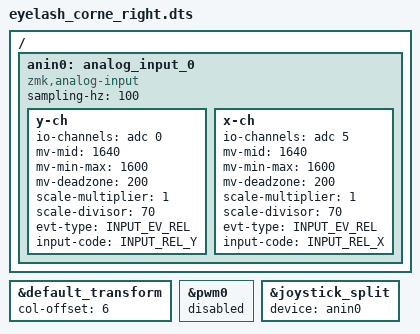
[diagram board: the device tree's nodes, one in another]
/*
*
* Copyright (c) 2024 The ZMK Contributors
* SPDX-License-Identifier: MIT
*
*/

#include "eyelash_corne.dtsi"
#include <zephyr/dt-bindings/input/input-event-codes.h>

&default_transform {
    col-offset = <6>;
};

&pwm0 {
    status = "disabled";
};

/ {
    anin0: analog_input_0 {
        compatible = "zmk,analog-input";
        sampling-hz = <100>;

        /* List adc 0 (Y) before adc 5 (X) to match SAADC ascending channel scan order. */
        y-ch {
            io-channels = <&adc 0>; // P0.02 (AIN0)
            mv-mid = <1640>;
            mv-min-max = <1600>;
            mv-deadzone = <200>;
            scale-multiplier = <1>;
            scale-divisor = <70>;
            evt-type = <INPUT_EV_REL>;
            input-code = <INPUT_REL_Y>;
        };
        x-ch {
            io-channels = <&adc 5>; // P0.29 (AIN5)
            mv-mid = <1640>;
            mv-min-max = <1600>;
            mv-deadzone = <200>;
            scale-multiplier = <1>;
            scale-divisor = <70>;
            evt-type = <INPUT_EV_REL>;
            input-code = <INPUT_REL_X>;
        };
    };
};

&joystick_split {
    device = <&anin0>;
};
